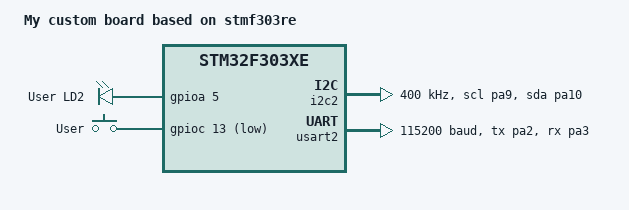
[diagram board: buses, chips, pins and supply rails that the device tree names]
/dts-v1/;

#include <st/f3/stm32f303Xe.dtsi>
#include <st/f3/stm32f303r(d-e)tx-pinctrl.dtsi>
#include <zephyr/dt-bindings/input/input-event-codes.h>


/ {
    model = "My custom board based on stmf303re";

    chosen {
        zephyr,console = &usart2;
        zephyr,shell-uart = &usart2;
        zephyr,sram = &sram0;
        zephyr,flash = &flash0;
    };

	leds: leds {    
		compatible = "gpio-leds";
		green_led_2: led_2 {
			gpios = <&gpioa 5 GPIO_ACTIVE_HIGH>;
			label = "User LD2";
		};
	};

	gpio_keys {
		compatible = "gpio-keys";
		user_button: button {
			label = "User";
			gpios = <&gpioc 13 GPIO_ACTIVE_LOW>;
			zephyr,code = <INPUT_KEY_0>;
		};
	};

	aliases {
		led0 = &green_led_2;
		sw0 = &user_button;
        imu-i2c = &i2c2;
	};
};

&clk_lsi {
    status = "okay";
};

&clk_hsi {
    status = "okay";
};

&pll {
    prediv = <1>;
    mul = <9>;
    clocks = <&clk_hsi>;
    status = "okay";
};

&rcc {
    clocks = <&pll>;
    clock-frequency = <DT_FREQ_M(72)>;
    ahb-prescaler = <1>;
    apb1-prescaler = <1>;
    apb2-prescaler = <1>;
    adc12-prescaler = <1>;
    adc34-prescaler = <1>;
};

&i2c2 {
    pinctrl-0 = <&i2c2_scl_pa9 &i2c2_sda_pa10>;
    pinctrl-names = "default";
    clock-frequency = <400000>;
    status = "okay";
};

&usart2 {
    pinctrl-0 = <&usart2_tx_pa2 &usart2_rx_pa3>;
    pinctrl-names = "default";
    current-speed = <115200>;
    status = "okay";
};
